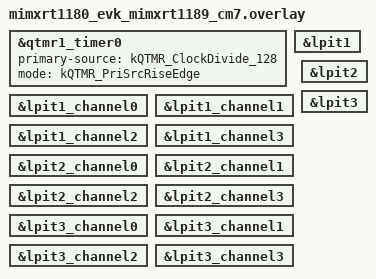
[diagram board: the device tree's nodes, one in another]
/*
 * Copyright 2024-2025 NXP
 *
 * SPDX-License-Identifier: Apache-2.0
 */

&qtmr1_timer0 {
	status = "okay";
	primary-source = "kQTMR_ClockDivide_128";
	mode = "kQTMR_PriSrcRiseEdge";
};

&lpit1 {
	status = "okay";
};

&lpit1_channel0 {
	status = "okay";
};

&lpit1_channel1 {
	status = "okay";
};

&lpit1_channel2 {
	status = "okay";
};

&lpit1_channel3 {
	status = "okay";
};

&lpit2 {
	status = "okay";
};

&lpit2_channel0 {
	status = "okay";
};

&lpit2_channel1 {
	status = "okay";
};

&lpit2_channel2 {
	status = "okay";
};

&lpit2_channel3 {
	status = "okay";
};

&lpit3 {
	status = "okay";
};

&lpit3_channel0 {
	status = "okay";
};

&lpit3_channel1 {
	status = "okay";
};

&lpit3_channel2 {
	status = "okay";
};

&lpit3_channel3 {
	status = "okay";
};
